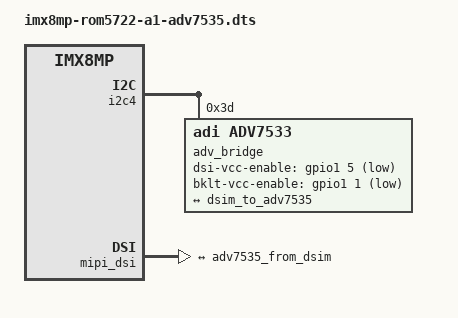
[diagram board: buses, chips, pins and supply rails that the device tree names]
// SPDX-License-Identifier: (GPL-2.0+ OR MIT)
/*
 * Copyright 2019 NXP
 */

#include "imx8mp-rom5722-a1.dts"

&i2c4 {
	adv_bridge: adv7535@3d {
		compatible = "adi,adv7533";
		reg = <0x3d>;
		adi,addr-cec = <0x3b>;
		adi,dsi-lanes = <4>;
		dsi-vcc-enable-gpio = <&gpio1 5 GPIO_ACTIVE_LOW>;	/* LCD1_VDD_EN */
		bklt-vcc-enable-gpio = <&gpio1 1 GPIO_ACTIVE_LOW>;	/* LCD1_BKLT_EN */
		status = "okay";

		port {
			adv7535_from_dsim: endpoint {
				remote-endpoint = <&dsim_to_adv7535>;
			};
		};
	};
};

&mipi_dsi {
	status = "okay";

	port@1 {
		dsim_to_adv7535: endpoint {
			remote-endpoint = <&adv7535_from_dsim>;
			attach-bridge;
		};
	};
};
